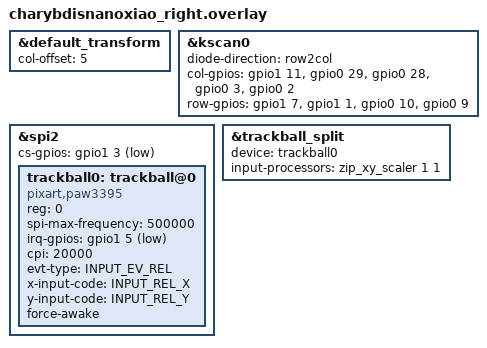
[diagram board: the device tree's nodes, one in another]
/*
 * Copyright (c) 2020 Pete Johanson
 *
 * SPDX-License-Identifier: MIT
 */

#include "charybdisnanoxiao.dtsi"
#include <zephyr/dt-bindings/input/input-event-codes.h>

&default_transform {
	col-offset = <5>;
};

&kscan0 {
  diode-direction = "row2col";
  col-gpios 
        = <&gpio1 11 (GPIO_ACTIVE_HIGH | GPIO_PULL_DOWN)>   //Col0
		, <&gpio0 29 (GPIO_ACTIVE_HIGH | GPIO_PULL_DOWN)>   //Col1
		, <&gpio0 28 (GPIO_ACTIVE_HIGH | GPIO_PULL_DOWN)>   //Col2
		, <&gpio0 3  (GPIO_ACTIVE_HIGH | GPIO_PULL_DOWN)>    //Col3
		, <&gpio0 2  (GPIO_ACTIVE_HIGH | GPIO_PULL_DOWN)>    //Col4
		;
  row-gpios
    = <&gpio1 7   GPIO_ACTIVE_HIGH>     //Row0
    , <&gpio1 1  GPIO_ACTIVE_HIGH>     //Row1
    , <&gpio0 10  GPIO_ACTIVE_HIGH>    //Row2
    , <&gpio0 9   GPIO_ACTIVE_HIGH>    //Row3
    ;
};

&spi2 {
    status = "okay";
	cs-gpios = <&gpio1 3 GPIO_ACTIVE_LOW>;

	trackball0: trackball@0 {
		compatible = "pixart,paw3395";
	    status = "okay";
		reg = <0>;
		//spi-max-frequency = <4000000>;
		spi-max-frequency = <500000>;

		// paw3395 driver parameters
		irq-gpios = <&gpio1 5 (GPIO_ACTIVE_LOW | GPIO_PULL_UP)>;
		cpi = <20000>;
		// swap-xy;  /* optional */
		// invert-x; /* optional */
		// invert-y; /* optional */
		evt-type = <INPUT_EV_REL>;
		x-input-code = <INPUT_REL_X>;
		y-input-code = <INPUT_REL_Y>;
        force-awake;
	};
};

&trackball_split {
    device = <&trackball0>;
    input-processors = <&zip_xy_scaler 1 1>;
};

